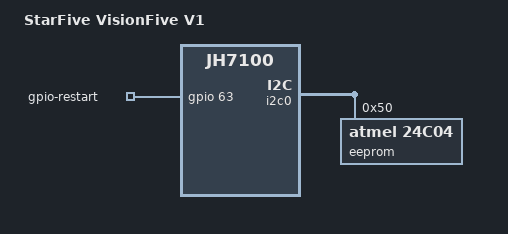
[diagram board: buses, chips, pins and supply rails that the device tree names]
// SPDX-License-Identifier: GPL-2.0 OR MIT
/*
 * Copyright (C) 2021 Emil Renner Berthing <kernel@esmil.dk>
 */

/dts-v1/;
#include "jh7100-common.dtsi"
#include <dt-bindings/gpio/gpio.h>

/ {
	model = "StarFive VisionFive V1";
	compatible = "starfive,visionfive-v1", "starfive,jh7100";

	gpio-restart {
		compatible = "gpio-restart";
		gpios = <&gpio 63 GPIO_ACTIVE_HIGH>;
		priority = <224>;
	};
};

&gpio {
	/* don't reset gpio mux for serial console and reset gpio */
	starfive,keep-gpiomux = <13 14 63>;
};

&i2c0 {
	eeprom@50 {
		compatible = "atmel,24c04";
		reg = <0x50>;
		pagesize = <16>;
	};
};
